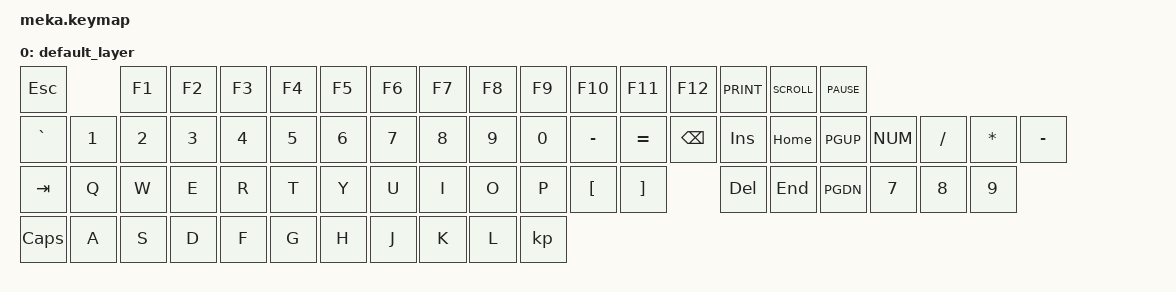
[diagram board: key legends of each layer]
#include <behaviors.dtsi>
#include <dt-bindings/zmk/keys.h>
#include <dt-bindings/zmk/bt.h>

/ {
        keymap {
                compatible = "zmk,keymap";

                default_layer {
            // -------------------------------------------------------------------------------------------------------------------------------------------------------------------------------------
            
			//   ESC   |       |  F1   |   F2  |   F3  |   F4  |   F5  |   F6  |   F7  |   F8  |   F9   |   F10  |  F11   |   F12  | PRINT  | SCROLL | PAUSE  |        |        |        |        
			//    `    |  1    |   2   |   3   |   4   |   5   |    6  |   7   |   8   |   9   |    0   |    -   |   =    |   BSPC |   INS  |  HOME  |  PGUP  |   NUM  |   /    |    *   |   -    
			//   TAB   |  Q    |   W   |   E   |   R   |   T   |    Y  |   U   |   I   |   O   |    P   |   [    |   ]    |        |   DEL  |  END   |  PGDN  |    7   |    8   |   9    |        
			//  CAPS   |  A    |   S   |   D   |   F   |   G   |    H  |   J   |   K   |   L   |    ;   |   '    |   \    |  ENTER |        |        |        |    4   |    5   |    6   |   +    
			//  LSHIFT |  \    |  Z    |   X   |   C   |   V   |    B  |   N   |   M   |   ,   |   .    |    /   |        | RSHIFT |        |   UP   |        |    1   |    2   |    3   |        
			//  LCTRL  |  FN   |  LALT |       |       | SPACE |       |       |       |  RALT |  WIN   |  COMMA |        | RCTRL  |  LEFT  |  DOWN  | RIGHT  |        |    0   |    .   | ENTER  
                        
						bindings = <
                &kp ESC                 &kp F1      &kp F2   &kp F3     &kp F4      &kp F5      &kp F6  &kp F7      &kp F8      &kp F9      &kp F10      &kp F11      &kp F12     &kp PRINT  &kp SCROLL  &kp PAUSE
				&kp `      &kp N1       &kp N2      &kp N3   &kp N4     &kp N5      &kp N6      &kp N7  &kp N8      &kp N9      &kp N0      &kp -        &kp =        &kp BSPC    &kp INS    &kp HOME    &kp PGUP    &kp NUM     &kp /   &kp *       &kp - 
                &kp TAB    &kp Q        &kp W       &kp E    &kp R      &kp T       &kp Y       &kp U   &kp I       &kp O       &kp P       &kp [        &kp ]                    &kp DEL    &kp END     &kp PGDN    &kp N7      &kp N8  &kp N9
				&kp CAPS   &kp A        &kp S       &kp D    &kp F      &kp G       &kp H       &kp J   &kp K       &kp L       &kp ;       &kp '        &kp \        &kp ENTER                                      &kp N4      &kp N5  &kp N6      &kp +
                &kp LSHFT  &kp \        &kp Z       &kp X    &kp C      &kp V       &kp B       &kp N   &kp M       &kp ,       &kp .       &kp /                     &kp RSHIFT             &kp UP                  &kp N1      &kp N2  &kp N3
                &kp LCTRL  &kp FN       &kp LALT                        &kp SPACE                                   &kp RALT    &kp WIN     &kp COMMA                 &kp RCTRL   &kp LEFT   &kp DOWN    &kp RIGHT               &kp N0  &kp .       &kp ENTER
                        >;
                };
            };
          }
